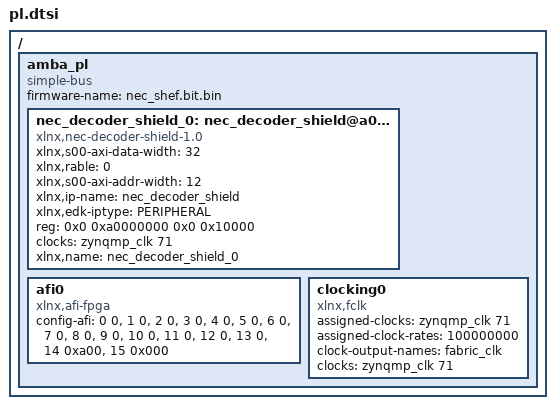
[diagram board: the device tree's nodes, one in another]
/ {
	amba_pl: amba_pl {
		ranges;
		compatible = "simple-bus";
		#address-cells = <2>;
		#size-cells = <2>;
		firmware-name = "nec_shef.bit.bin";
		nec_decoder_shield_0: nec_decoder_shield@a0000000 {
			xlnx,s00-axi-data-width = <32>;
			xlnx,rable = <0>;
			compatible = "xlnx,nec-decoder-shield-1.0";
			status = "okay";
			clock-names = "s00_axi_aclk";
			xlnx,s00-axi-addr-width = <12>;
			xlnx,ip-name = "nec_decoder_shield";
			xlnx,edk-iptype = "PERIPHERAL";
			reg = <0x0 0xa0000000 0x0 0x10000>;
			clocks = <&zynqmp_clk 71>;
			xlnx,name = "nec_decoder_shield_0";
		};
		afi0: afi0 {
			status = "okay";
			compatible = "xlnx,afi-fpga";
			config-afi = < 0 0>, <1 0>, <2 0>, <3 0>, <4 0>, <5 0>, <6 0>, <7 0>, <8 0>, <9 0>, <10 0>, <11 0>, <12 0>, <13 0>, <14 0xa00>, <15 0x000>;
		};
		clocking0: clocking0 {
			compatible = "xlnx,fclk";
			assigned-clocks = <&zynqmp_clk 71>;
			assigned-clock-rates = <100000000>;
			#clock-cells = <0>;
			clock-output-names = "fabric_clk";
			clocks = <&zynqmp_clk 71>;
		};
	};
};
